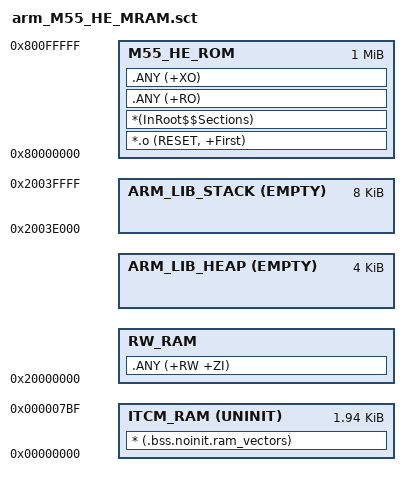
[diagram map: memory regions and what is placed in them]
; These are now processed from toolchain cmake file
;#! armclang -E --target=arm-arm-none-eabi -mcpu=cortex-m55 -xc
; command above MUST be in first line (no comment above!)

/*
;-------- <<< Use Configuration Wizard in Context Menu >>> -------------------
*/

/* MRAM code storage for M55-HE */
#define __ROM_BASE      0x80000000
#define __ROM_SIZE      0x00100000

/*--------------------- ITCM Configuration ----------------------------------
; <h> ITCM Configuration
;   <o0> ITCM Base Address <0x0-0xFFFFFFFF:8>
;   <o1> ITCM Size (in Bytes) <0x0-0xFFFFFFFF:8>
; </h>
 *----------------------------------------------------------------------------*/
/* SRAM4 is mapped as ITCM in M55-HE */
#define __ITCM_BASE       0x00000000
#define __ITCM_SIZE       0x00040000

/*--------------------- DTCM Configuration ---------------------------
; <h> DTCM Configuration
;   <o0> DTCM Base Address    <0x0-0xFFFFFFFF:8>
;   <o1> DTCM Size (in Bytes) <0x0-0xFFFFFFFF:8>
; </h>
 *----------------------------------------------------------------------------*/
/* SRAM5 is mapped as DTCM in M55-HE */
#define __RAM_BASE        0x20000000
#define __RAM_SIZE        0x00040000

/*--------------------- Stack / Heap Configuration ---------------------------
; <h> Stack / Heap Configuration
;   <o0> Stack Size (in Bytes) <0x0-0xFFFFFFFF:8>
;   <o1> Heap Size (in Bytes) <0x0-0xFFFFFFFF:8>
;   <o2> App Heap Size (in Bytes) <0x0-0xFFFFFFFF:8>
; </h>
 *----------------------------------------------------------------------------*/
#define __VECTORS_SIZE    (496 * 4)
#define __STACK_SIZE      0x00002000
#define __HEAP_SIZE       0x00001000
#define __APP_HEAP_SIZE   0x00004000
/*
;------------- <<< end of configuration section >>> ---------------------------
*/


/*----------------------------------------------------------------------------
  User Stack & Heap boundary definition
 *----------------------------------------------------------------------------*/
#define __STACK_TOP     (__RAM_BASE + __RAM_SIZE)    /* starts at end of RAM */
#define __HEAP_BASE     (AlignExpr(+0, 8))           /* starts after RW_RAM section, 8 byte aligned */
#define __APP_HEAP_BASE (AlignExpr(+0, 8))           /* starts after HEAP, 8 byte aligned */


/*----------------------------------------------------------------------------
  Scatter File Definitions definition
 *----------------------------------------------------------------------------*/

#define __RW_BASE      __RAM_BASE
#define __RW_SIZE     (__RAM_SIZE - __STACK_SIZE - __HEAP_SIZE - __APP_HEAP_SIZE)

LR_ROM __ROM_BASE NOCOMPRESS __ROM_SIZE  {    ; load region size_region
  M55_HE_ROM +0 __ROM_SIZE  {                 ; load address = execution address
   *.o (RESET, +First)
   *(InRoot$$Sections)
   .ANY (+RO)
   .ANY (+XO)
  }

  ITCM_RAM __ITCM_BASE UNINIT ALIGN 2048 __VECTORS_SIZE {
   * (.bss.noinit.ram_vectors)
  }


  RW_RAM __RW_BASE {                     ; RW data
   .ANY (+RW +ZI)
  }

#if __HEAP_SIZE > 0
  ARM_LIB_HEAP  __HEAP_BASE EMPTY  __HEAP_SIZE  {   ; Reserve empty region for heap
  }
#endif

  ARM_LIB_STACK __STACK_TOP EMPTY -__STACK_SIZE {   ; Reserve empty region for stack
  }
}
